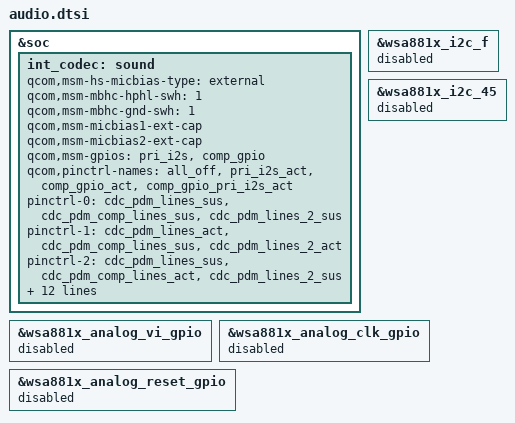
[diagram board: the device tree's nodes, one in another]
/* msm-audio */
&soc {
	int_codec: sound {
	status = "ok";
	qcom,msm-hs-micbias-type = "external";
	qcom,msm-mbhc-hphl-swh = <1>;
	qcom,msm-mbhc-gnd-swh = <1>;
	qcom,msm-micbias1-ext-cap;
	qcom,msm-micbias2-ext-cap;
	//qcom,cdc-us-euro-gpios;
	qcom,msm-gpios =
		"pri_i2s",
		"comp_gpio";
	qcom,pinctrl-names =
		"all_off",
		"pri_i2s_act",
		"comp_gpio_act",
		"comp_gpio_pri_i2s_act";
	pinctrl-names =
		"all_off",
		"pri_i2s_act",
		"comp_gpio_act",
		"comp_gpio_pri_i2s_act";
	pinctrl-0 = <&cdc_pdm_lines_sus &cdc_pdm_comp_lines_sus
		&cdc_pdm_lines_2_sus>;
	pinctrl-1 = <&cdc_pdm_lines_act &cdc_pdm_comp_lines_sus
		&cdc_pdm_lines_2_act>;
	pinctrl-2 = <&cdc_pdm_lines_sus &cdc_pdm_comp_lines_act
		&cdc_pdm_lines_2_sus>;
	pinctrl-3 = <&cdc_pdm_lines_act &cdc_pdm_comp_lines_act
		&cdc_pdm_lines_2_act>;
	qcom,spk_ext_pa = <&tlmm 139 0x0>;
	qcom,audio-routing =
		"RX_BIAS", "MCLK",
		"SPK_RX_BIAS", "MCLK",
		"INT_LDO_H", "MCLK",
		"MIC BIAS External", "Handset Mic",
		"MIC BIAS External2", "Headset Mic",
		"MIC BIAS External", "Secondary Mic",
		"AMIC1", "MIC BIAS External",
		"AMIC2", "MIC BIAS External2",
		"AMIC3", "MIC BIAS External";
	};
};
&wsa881x_i2c_f {
	status = "disabled";
};
&wsa881x_i2c_45 {
	status = "disabled";
};
/* Custom changes */
&wsa881x_analog_vi_gpio {
        status = "disabled";
};

&wsa881x_analog_clk_gpio {
        status = "disabled";
};

&wsa881x_analog_reset_gpio {
        status = "disabled";
};
/* msm8953-audio */
&int_codec {
    qcom,msm-ext-pa = "primary";
	qcom,msm-mclk-freq = <9600000>;
	/delete-property/qcom,cdc-us-euro-gpios;
	/delete-property/asoc-wsa-codec-names;
	/delete-property/asoc-wsa-codec-prefixes;
	
};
